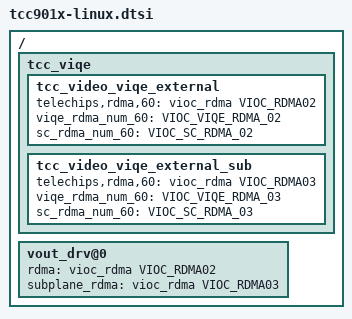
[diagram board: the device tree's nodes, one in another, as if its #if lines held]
/*
 * Device tree for Telechips TCC901x Linux platform
 *
 * Copyright (C) 2019 Telechips Inc. - http://www.telechips.com
 *
 * This file is dual-licensed: you can use it either under the terms
 * of the GPL or the X11 license, at your option. Note that this dual
 * licensing only applies to this file, and not this project as a
 * whole.
 *
 *  a) This file is free software; you can redistribute it and/or
 *     modify it under the terms of the GNU General Public License as
 *     published by the Free Software Foundation; either version 2 of the
 *     License, or (at your option) any later version.
 *
 *     This file is distributed in the hope that it will be useful,
 *     but WITHOUT ANY WARRANTY; without even the implied warranty of
 *     MERCHANTABILITY or FITNESS FOR A PARTICULAR PURPOSE.  See the
 *     GNU General Public License for more details.
 *
 * Or, alternatively,
 *
 *  b) Permission is hereby granted, free of charge, to any person
 *     obtaining a copy of this software and associated documentation
 *     files (the "Software"), to deal in the Software without
 *     restriction, including without limitation the rights to use,
 *     copy, modify, merge, publish, distribute, sublicense, and/or
 *     sell copies of the Software, and to permit persons to whom the
 *     Software is furnished to do so, subject to the following
 *     conditions:
 *
 *     The above copyright notice and this permission notice shall be
 *     included in all copies or substantial portions of the Software.
 *
 *     THE SOFTWARE IS PROVIDED "AS IS", WITHOUT WARRANTY OF ANY KIND,
 *     EXPRESS OR IMPLIED, INCLUDING BUT NOT LIMITED TO THE WARRANTIES
 *     OF MERCHANTABILITY, FITNESS FOR A PARTICULAR PURPOSE AND
 *     NONINFRINGEMENT. IN NO EVENT SHALL THE AUTHORS OR COPYRIGHT
 *     HOLDERS BE LIABLE FOR ANY CLAIM, DAMAGES OR OTHER LIABILITY,
 *     WHETHER IN AN ACTION OF CONTRACT, TORT OR OTHERWISE, ARISING
 *     FROM, OUT OF OR IN CONNECTION WITH THE SOFTWARE OR THE USE OR
 *     OTHER DEALINGS IN THE SOFTWARE.
 */

#ifdef CONFIG_VIOC_DOLBY_VISION_EDR
/{
	tcc_viqe {
		tcc_video_viqe_external {
			telechips,rdma,60 = <&vioc_rdma VIOC_RDMA02>;
			viqe_rdma_num_60 = <VIOC_VIQE_RDMA_02>;
			sc_rdma_num_60 = <VIOC_SC_RDMA_02>;
		};

		tcc_video_viqe_external_sub {
			telechips,rdma,60 = <&vioc_rdma VIOC_RDMA03>;
			viqe_rdma_num_60 = <VIOC_VIQE_RDMA_03>;
			sc_rdma_num_60 = <VIOC_SC_RDMA_03>;
		};
	};

	vout_drv@0 {
		rdma = <&vioc_rdma VIOC_RDMA02>;
		subplane_rdma = <&vioc_rdma VIOC_RDMA03>;
	};
};
#endif

